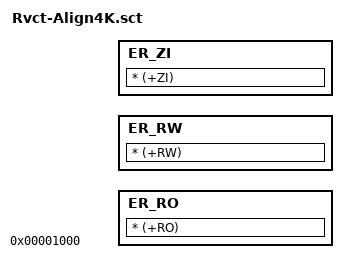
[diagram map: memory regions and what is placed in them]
/** @file

  Copyright (c) 2015, Linaro Ltd. All rights reserved.<BR>

  SPDX-License-Identifier: BSD-2-Clause-Patent

**/

REGION 0x1000 RELOC {
  ER_RO +0 ALIGN 4096 {
    * (+RO)
  }
  ER_RW +0 ALIGN 4096 {
    * (+RW)
  }
  ER_ZI +0 {
    * (+ZI)
  }
}
